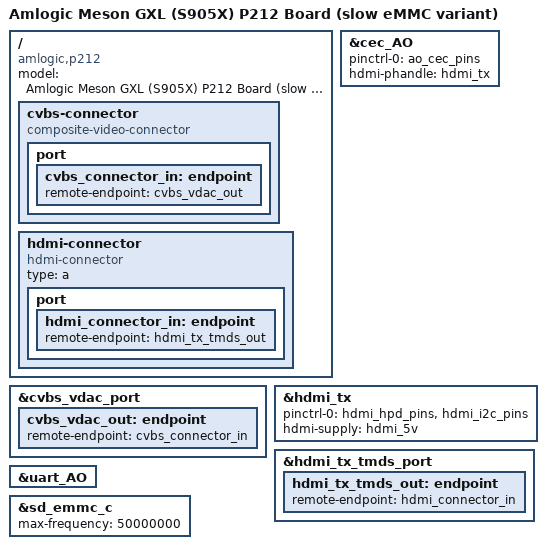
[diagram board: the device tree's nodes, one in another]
// SPDX-License-Identifier: (GPL-2.0+ OR MIT)
/*
 * Copyright (c) 2016 Endless Computers, Inc.
 * Author: Carlo Caione <carlo@endlessm.com>
 */

/dts-v1/;

#include "meson-gxl-s905x-p212.dtsi"

/ {
	compatible = "amlogic,p212", "amlogic,s905x", "amlogic,meson-gxl";
	model = "Amlogic Meson GXL (S905X) P212 Board (slow eMMC variant)";

	cvbs-connector {
		compatible = "composite-video-connector";

		port {
			cvbs_connector_in: endpoint {
				remote-endpoint = <&cvbs_vdac_out>;
			};
		};
	};

	hdmi-connector {
		compatible = "hdmi-connector";
		type = "a";

		port {
			hdmi_connector_in: endpoint {
				remote-endpoint = <&hdmi_tx_tmds_out>;
			};
		};
	};
};

&cec_AO {
	status = "okay";
	pinctrl-0 = <&ao_cec_pins>;
	pinctrl-names = "default";
	hdmi-phandle = <&hdmi_tx>;
};

&cvbs_vdac_port {
	cvbs_vdac_out: endpoint {
		remote-endpoint = <&cvbs_connector_in>;
	};
};

&hdmi_tx {
	status = "okay";
	pinctrl-0 = <&hdmi_hpd_pins>, <&hdmi_i2c_pins>;
	pinctrl-names = "default";
	hdmi-supply = <&hdmi_5v>;
};

&hdmi_tx_tmds_port {
	hdmi_tx_tmds_out: endpoint {
		remote-endpoint = <&hdmi_connector_in>;
	};
};

/* This UART is brought out to the DB9 connector */
&uart_AO {
	status = "okay";
};

/*
 * Slow eMMC variant: some S905L boxes (e.g. "slowemmc" China TV boxes) hang
 * during eMMC enumeration at HS200 200MHz.  Cap the eMMC to 50MHz highspeed
 * only, mirroring the old Amlogic BSP gxl_p212_1g_slowemmc.dtb behaviour.
 */
&sd_emmc_c {
	/delete-property/ mmc-hs200-1_8v;
	/delete-property/ mmc-ddr-1_8v;
	/delete-property/ cap-mmc-highspeed;
	max-frequency = <50000000>;
};
